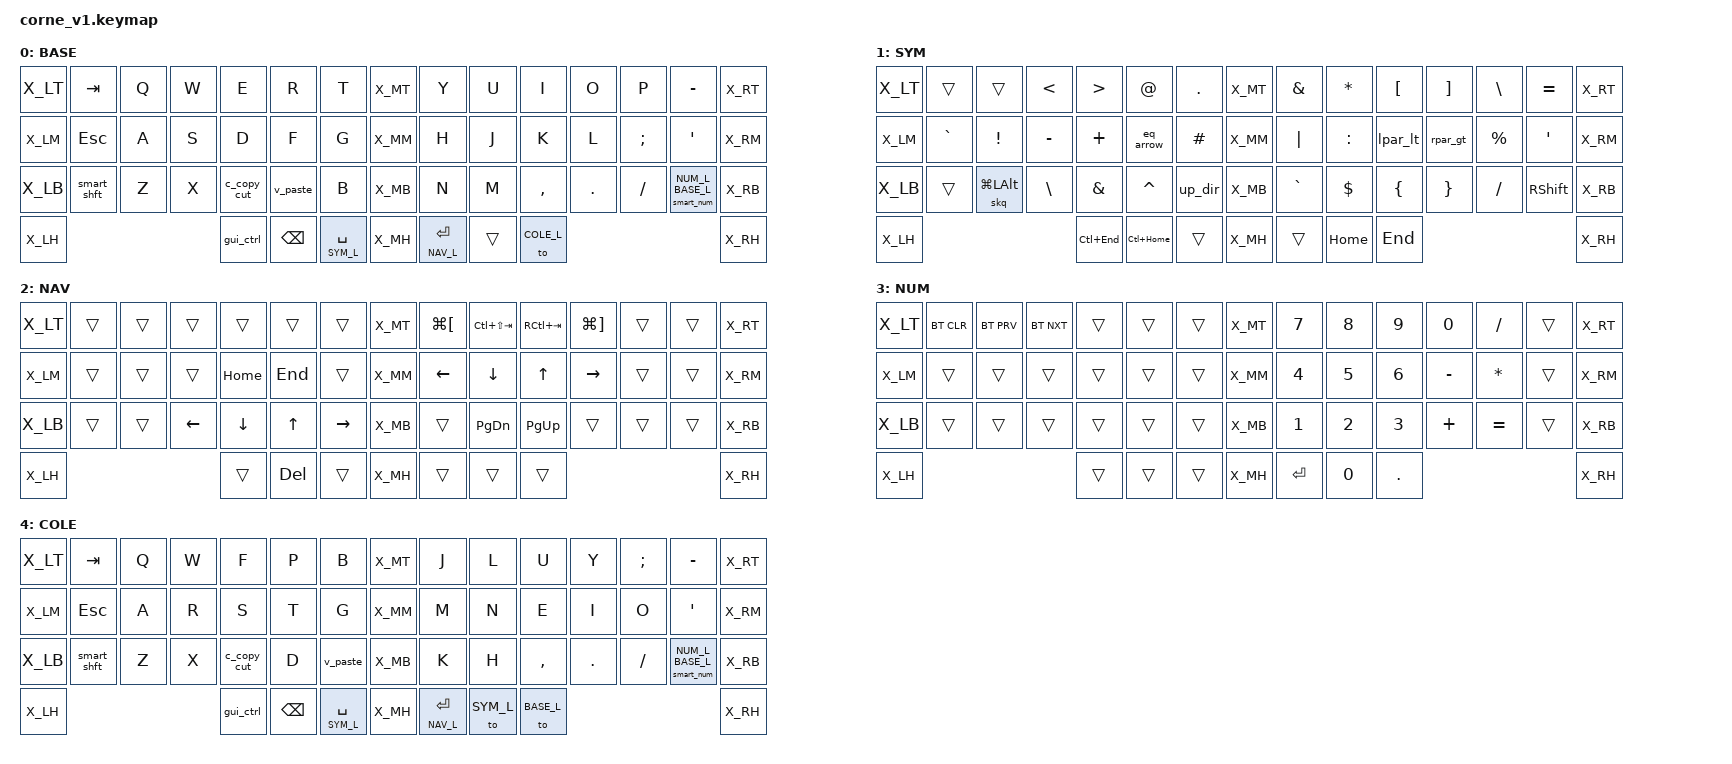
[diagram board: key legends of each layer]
/*
 * Copyright (c) 2020 The ZMK Contributors
 *
 * SPDX-License-Identifier: MIT
 */

#include <behaviors.dtsi>
#include <dt-bindings/zmk/keys.h>
#include <dt-bindings/zmk/bt.h>

#include "../zmk-nodefree-config/helper.h"

#define BASE_L 0
#define SYM_L 1
#define NAV_L 2
#define NUM_L 3
#define COLE_L 4

// #include "combos.dtsi"  // requires layer aliases
// #include "mouse.dtsi"
#include "extra_keys.h"

#define XXX &none
#define ___ &trans

/* Global settings */

#define QUICK_TAP_MS 175

&lt {  // layer-tap config
    flavor = "balanced";
    tapping-term-ms = <200>;
    quick-tap-ms = <QUICK_TAP_MS>;
};

&mt {
    flavor = "tap-preferred";
    tapping-term-ms = <200>;
};

// sticky quick release
ZMK_BEHAVIOR(skq, sticky_key,
    release-after-ms = <1000>;
    quick-release;
    ignore-modifiers;
    bindings = <&kp>;
)

/* Caps-word, num-word and smart-mouse */
// tap: sticky-shift | shift + tap/ double-tap: caps-word | hold: shift
ZMK_BEHAVIOR(smart_shft, mod_morph,
    bindings = <&sk LSHFT>, <&caps_word>;
    mods = <(MOD_LSFT)>;
)
&caps_word {  // mods deactivate caps-word, requires PR #1441
    /delete-property/ ignore-modifiers;
};

// tap: num-word | double-tap: sticky num-layer | hold: num-layer
#define SMART_NUM &smart_num NUM_L BASE_L
ZMK_BEHAVIOR(smart_num, hold_tap,
    flavor = "balanced";
    tapping-term-ms = <200>;
    quick-tap-ms = <QUICK_TAP_MS>;
    bindings = <&mo>, <&num_dance>;
)
ZMK_BEHAVIOR(num_dance, tap_dance,
    tapping-term-ms = <200>;
    bindings = <&num_word>, <&sl NUM_L>;  // reverse this for sticky-num on single tap
)
&num_word {  // num-word, requires PR #1441
    layers = <NUM_L>;
    continue-list = <BSPC DEL DOT COMMA PLUS MINUS STAR FSLH EQUAL>;
};

// tap: comma | shift + tap: semicolon | ctrl + shift + tap: <
ZMK_BEHAVIOR(comma_morph, mod_morph,
    mods = <(MOD_LSFT|MOD_RSFT)>;
    bindings = <&kp COMMA>, <&comma_inner_morph>;
)
ZMK_BEHAVIOR(comma_inner_morph, mod_morph,
    bindings = <&kp SEMICOLON>, <&kp LESS_THAN>;
    mods = <(MOD_LCTL|MOD_RCTL)>;
)

// tap: dot | shift + tap: colon | ctrl + shift + tap: >
ZMK_BEHAVIOR(dot_morph, mod_morph,
    bindings = <&kp DOT>, <&dot_inner_morph>;
    mods = <(MOD_LSFT|MOD_RSFT)>;
)
ZMK_BEHAVIOR(dot_inner_morph, mod_morph,
    bindings = <&kp COLON>, <&kp GREATER_THAN>;
    mods = <(MOD_LCTL|MOD_RCTL)>;
)

// tap: left-parenthesis | shft + tap: less-than
ZMK_BEHAVIOR(lpar_lt, mod_morph,
    bindings = <&kp LPAR>, <&kp LT>;
    mods = <(MOD_LSFT|MOD_RSFT)>;
)

// tap: right-parenthesis | shft + tap: greater-than
ZMK_BEHAVIOR(rpar_gt, mod_morph,
    bindings = <&kp RPAR>, <&kp GT>;
    mods = <(MOD_LSFT|MOD_RSFT)>;
)

// tap: c | doube-tap: copy | triple-tap: cut
ZMK_BEHAVIOR(c_copy_cut, tap_dance,
    tapping-term-ms = <200>;
    bindings = <&kp C>, <&kp LG(C)>, <&kp LG(X)>;
)

// tap: v | doube-tap: paste
ZMK_BEHAVIOR(v_paste, tap_dance,
    tapping-term-ms = <200>;
    bindings = <&kp V>, <&kp LG(V)>;
)
// tap: gui | doube-tap: ctrl
ZMK_BEHAVIOR(gui_ctrl, tap_dance,
    tapping-term-ms = <200>;
    bindings = <&skq LGUI>, <&skq LCTRL>;
)

/* coding */
ZMK_BEHAVIOR(up_dir, macro,
    bindings = <&macro_tap &kp DOT>, <&macro_tap &kp DOT>, <&macro_tap &kp FSLH>;
)
ZMK_BEHAVIOR(arrow_fn, macro,
    bindings = <&macro_tap &kp EQUAL>, <&macro_tap &kp GT>;
)
// tap: = | doube-tap: =>
ZMK_BEHAVIOR(eq_arrow, tap_dance,
    tapping-term-ms = <200>;
    bindings = <&kp EQUAL>, <&arrow_fn>;
)

// tap: toggle NUM_L | hold: NAV_L
ZMK_BEHAVIOR(num_nav, tap_dance,
    tapping-term-ms = <150>;
    bindings = <&to NUM_L>, <&mo NAV_L>;
)

ZMK_LAYER(BASE,
    //╭──────╮ ╭─────────────┬─────────────┬─────────────┬─────────────┬─────────────┬─────────────╮ ╭──────╮ ╭─────────────┬─────────────┬─────────────┬─────────────┬─────────────┬─────────────╮ ╭──────╮
        X_LT     &kp TAB       &kp Q         &kp W         &kp E         &kp R         &kp T           X_MT     &kp Y         &kp U         &kp I         &kp O         &kp P         &kp MINUS       X_RT
    //├──────┤ ├─────────────┼─────────────┼─────────────┼─────────────┼─────────────┼─────────────┤ ├──────┤ ├─────────────┼─────────────┼─────────────┼─────────────┼─────────────┼─────────────┤ ├──────┤
        X_LM     &kp ESC       &kp A         &kp S         &kp D         &kp F         &kp G           X_MM     &kp H         &kp J         &kp K         &kp L         &kp SEMI      &kp SQT         X_RM
    //├──────┤ ├─────────────┼─────────────┼─────────────┼─────────────┼─────────────┼─────────────┤ ├──────┤ ├─────────────┼─────────────┼─────────────┼─────────────┼─────────────┼─────────────┤ ├──────┤
        X_LB     &smart_shft   &kp Z         &kp X         &c_copy_cut   &v_paste      &kp B           X_MB     &kp N         &kp M         &kp COMMA     &kp DOT       &kp FSLH      SMART_NUM       X_RB
    //├──────┤ ╰─────────────┴─────────────┴─────────────┼─────────────┼─────────────┼─────────────┤ ├──────┤ ├─────────────┼─────────────┼─────────────┴─────────────┴─────────────┴─────────────╯ ├──────┤
        X_LH                                               &gui_ctrl     &kp BSPC      &lt SYM_L SPACE X_MH     &lt NAV_L RET ___           &to COLE_L                                                X_RH
    //╰──────╯                                           ╰─────────────┴─────────────┴─────────────╯ ╰──────╯ ╰─────────────┴─────────────┴─────────────╯                                           ╰──────╯
)

ZMK_LAYER(SYM,
    //╭──────╮ ╭─────────────┬─────────────┬─────────────┬─────────────┬─────────────┬─────────────╮ ╭──────╮ ╭─────────────┬─────────────┬─────────────┬─────────────┬─────────────┬─────────────╮ ╭──────╮
        X_LT     ___           ___           &kp LT        &kp GT        &kp AT        &kp DOT         X_MT     &kp AMPS      &kp STAR      &kp LBKT      &kp RBKT      &kp BSLH      &kp EQUAL       X_RT
    //├──────┤ ├─────────────┼─────────────┼─────────────┼─────────────┼─────────────┼─────────────┤ ├──────┤ ├─────────────┼─────────────┼─────────────┼─────────────┼─────────────┼─────────────┤ ├──────┤
        X_LM     &kp GRAVE     &kp EXCL      &kp MINUS     &kp PLUS      &eq_arrow     &kp HASH        X_MM     &kp PIPE      &kp COLON     &lpar_lt      &rpar_gt      &kp PRCNT     &kp SQT         X_RM
    //├──────┤ ├─────────────┼─────────────┼─────────────┼─────────────┼─────────────┼─────────────┤ ├──────┤ ├─────────────┼─────────────┼─────────────┼─────────────┼─────────────┼─────────────┤ ├──────┤
        X_LB     ___           &skq LG(LALT) &kp BSLH      &kp AMPS      &kp CARET     &up_dir         X_MB     &kp GRAVE     &kp DLLR      &kp LBRC      &kp RBRC      &kp FSLH      &kp RSHFT       X_RB
    //├──────┤ ╰─────────────┴─────────────┴─────────────┼─────────────┼─────────────┼─────────────┤ ├──────┤ ├─────────────┼─────────────┼─────────────┴─────────────┴─────────────┴─────────────╯ ├──────┤
        X_LH                                               &kp LC(END)   &kp LC(HOME)  ___             X_MH     ___           &kp HOME      &kp END                                                   X_RH
    //╰──────╯                                           ╰─────────────┴─────────────┴─────────────╯ ╰──────╯ ╰─────────────┴─────────────┴─────────────╯                                           ╰──────╯
)

ZMK_LAYER(NAV,
    //╭──────╮ ╭─────────────┬─────────────┬─────────────┬─────────────┬─────────────┬─────────────╮ ╭──────╮ ╭─────────────┬─────────────┬─────────────┬─────────────┬─────────────┬─────────────╮ ╭──────╮
        X_LT     ___           ___           ___           ___           ___           ___             X_MT     &kp LG(LBKT)  &kp LC(LS(TAB)) &kp RC(TAB) &kp LG(RBKT)  ___           ___            X_RT
    //├──────┤ ├─────────────┼─────────────┼─────────────┼─────────────┼─────────────┼─────────────┤ ├──────┤ ├─────────────┼─────────────┼─────────────┼─────────────┼─────────────┼─────────────┤ ├──────┤
        X_LM     ___           ___           ___           &kp HOME      &kp END       ___             X_MM     &kp LEFT      &kp DOWN      &kp UP        &kp RIGHT     ___           ___             X_RM
    //├──────┤ ├─────────────┼─────────────┼─────────────┼─────────────┼─────────────┼─────────────┤ ├──────┤ ├─────────────┼─────────────┼─────────────┼─────────────┼─────────────┼─────────────┤ ├──────┤
        X_LB     ___           ___           &kp LEFT      &kp DOWN      &kp UP        &kp RIGHT       X_MB     ___           &kp PG_DN     &kp PG_UP     ___           ___           ___             X_RB
    //├──────┤ ╰─────────────┴─────────────┴─────────────┼─────────────┼─────────────┼─────────────┤ ├──────┤ ├─────────────┼─────────────┼─────────────┴─────────────┴─────────────┴─────────────╯ ├──────┤
        X_LH                                               ___           &kp DEL       ___             X_MH     ___           ___           ___                                                       X_RH
    //╰──────╯                                           ╰─────────────┴─────────────┴─────────────╯ ╰──────╯ ╰─────────────┴─────────────┴─────────────╯                                           ╰──────╯
)

ZMK_LAYER(NUM,
    //╭──────╮ ╭─────────────┬─────────────┬─────────────┬─────────────┬─────────────┬─────────────╮ ╭──────╮ ╭─────────────┬─────────────┬─────────────┬─────────────┬─────────────┬─────────────╮ ╭──────╮
        X_LT     &bt BT_CLR    &bt BT_PRV    &bt BT_NXT    ___           ___           ___             X_MT     &kp N7        &kp N8        &kp N9        &kp N0        &kp FSLH      ___             X_RT
    //├──────┤ ├─────────────┼─────────────┼─────────────┼─────────────┼─────────────┼─────────────┤ ├──────┤ ├─────────────┼─────────────┼─────────────┼─────────────┼─────────────┼─────────────┤ ├──────┤
        X_LM     ___           ___           ___           ___           ___           ___             X_MM     &kp N4        &kp N5        &kp N6        &kp MINUS     &kp STAR      ___             X_RM
    //├──────┤ ├─────────────┼─────────────┼─────────────┼─────────────┼─────────────┼─────────────┤ ├──────┤ ├─────────────┼─────────────┼─────────────┼─────────────┼─────────────┼─────────────┤ ├──────┤
        X_LB     ___           ___           ___           ___           ___           ___             X_MB     &kp N1        &kp N2        &kp N3        &kp PLUS      &kp EQUAL     ___             X_RB
    //├──────┤ ╰─────────────┴─────────────┴─────────────┼─────────────┼─────────────┼─────────────┤ ├──────┤ ├─────────────┼─────────────┼─────────────┴─────────────┴─────────────┴─────────────╯ ├──────┤
        X_LH                                               ___           ___           ___             X_MH     &kp RET       &kp N0        &kp DOT                                                   X_RH
    //╰──────╯                                           ╰─────────────┴─────────────┴─────────────╯ ╰──────╯ ╰─────────────┴─────────────┴─────────────╯                                           ╰──────╯
)

ZMK_LAYER(COLE,
    //╭──────╮ ╭─────────────┬─────────────┬─────────────┬─────────────┬─────────────┬─────────────╮ ╭──────╮ ╭─────────────┬─────────────┬─────────────┬─────────────┬─────────────┬─────────────╮ ╭──────╮
        X_LT     &kp TAB       &kp Q         &kp W         &kp F         &kp P         &kp B           X_MT     &kp J         &kp L         &kp U         &kp Y         &kp SEMI      &kp MINUS       X_RT
    //├──────┤ ├─────────────┼─────────────┼─────────────┼─────────────┼─────────────┼─────────────┤ ├──────┤ ├─────────────┼─────────────┼─────────────┼─────────────┼─────────────┼─────────────┤ ├──────┤
        X_LM     &kp ESC       &kp A         &kp R         &kp S         &kp T         &kp G           X_MM     &kp M         &kp N         &kp E         &kp I         &kp O         &kp SQT         X_RM
    //├──────┤ ├─────────────┼─────────────┼─────────────┼─────────────┼─────────────┼─────────────┤ ├──────┤ ├─────────────┼─────────────┼─────────────┼─────────────┼─────────────┼─────────────┤ ├──────┤
        X_LB     &smart_shft   &kp Z         &kp X         &c_copy_cut   &kp D         &v_paste        X_MB     &kp K         &kp H         &kp COMMA     &kp DOT       &kp FSLH      SMART_NUM       X_RB
    //├──────┤ ╰─────────────┴─────────────┴─────────────┼─────────────┼─────────────┼─────────────┤ ├──────┤ ├─────────────┼─────────────┼─────────────┴─────────────┴─────────────┴─────────────╯ ├──────┤
        X_LH                                               &gui_ctrl     &kp BSPC      &lt SYM_L SPACE X_MH     &lt NAV_L RET &to SYM_L     &to BASE_L                                                X_RH
    //╰──────╯                                           ╰─────────────┴─────────────┴─────────────╯ ╰──────╯ ╰─────────────┴─────────────┴─────────────╯                                           ╰──────╯
)
